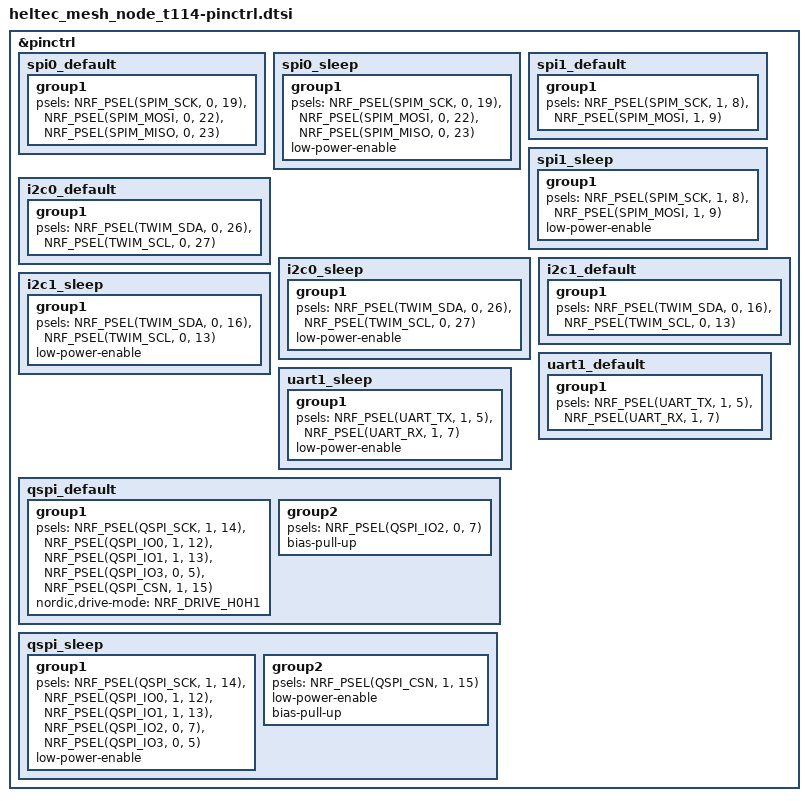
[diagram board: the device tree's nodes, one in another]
/*
 * Copyright (c) 2026 Yeray Lois Sanchez
 *
 * SPDX-License-Identifier: Apache-2.0
 */

&pinctrl {
	spi0_default: spi0_default {
		group1 {
			psels = <NRF_PSEL(SPIM_SCK, 0, 19)>,
				<NRF_PSEL(SPIM_MOSI, 0, 22)>,
				<NRF_PSEL(SPIM_MISO, 0, 23)>;
		};
	};

	spi0_sleep: spi0_sleep {
		group1 {
			psels = <NRF_PSEL(SPIM_SCK, 0, 19)>,
				<NRF_PSEL(SPIM_MOSI, 0, 22)>,
				<NRF_PSEL(SPIM_MISO, 0, 23)>;
			low-power-enable;
		};
	};

	spi1_default: spi1_default {
		group1 {
			psels = <NRF_PSEL(SPIM_SCK, 1, 8)>,
				<NRF_PSEL(SPIM_MOSI, 1, 9)>;
		};
	};

	spi1_sleep: spi1_sleep {
		group1 {
			psels = <NRF_PSEL(SPIM_SCK, 1, 8)>,
				<NRF_PSEL(SPIM_MOSI, 1, 9)>;
			low-power-enable;
		};
	};

	i2c0_default: i2c0_default {
		group1 {
			psels = <NRF_PSEL(TWIM_SDA, 0, 26)>,
				<NRF_PSEL(TWIM_SCL, 0, 27)>;
		};
	};

	i2c0_sleep: i2c0_sleep {
		group1 {
			psels = <NRF_PSEL(TWIM_SDA, 0, 26)>,
				<NRF_PSEL(TWIM_SCL, 0, 27)>;
			low-power-enable;
		};
	};

	i2c1_default: i2c1_default {
		group1 {
			psels = <NRF_PSEL(TWIM_SDA, 0, 16)>,
				<NRF_PSEL(TWIM_SCL, 0, 13)>;
		};
	};

	i2c1_sleep: i2c1_sleep {
		group1 {
			psels = <NRF_PSEL(TWIM_SDA, 0, 16)>,
				<NRF_PSEL(TWIM_SCL, 0, 13)>;
			low-power-enable;
		};
	};

	uart1_default: uart1_default {
		group1 {
			psels = <NRF_PSEL(UART_TX, 1, 5)>,
				<NRF_PSEL(UART_RX, 1, 7)>;
		};
	};

	uart1_sleep: uart1_sleep {
		group1 {
			psels = <NRF_PSEL(UART_TX, 1, 5)>,
				<NRF_PSEL(UART_RX, 1, 7)>;
			low-power-enable;
		};
	};

	qspi_default: qspi_default {
		group1 {
			psels = <NRF_PSEL(QSPI_SCK, 1, 14)>,
				<NRF_PSEL(QSPI_IO0, 1, 12)>,
				<NRF_PSEL(QSPI_IO1, 1, 13)>,
				<NRF_PSEL(QSPI_IO3, 0, 5)>,
				<NRF_PSEL(QSPI_CSN, 1, 15)>;
			nordic,drive-mode = <NRF_DRIVE_H0H1>;
		};

		group2 {
			psels = <NRF_PSEL(QSPI_IO2, 0, 7)>;
			bias-pull-up;
		};
	};

	qspi_sleep: qspi_sleep {
		group1 {
			psels = <NRF_PSEL(QSPI_SCK, 1, 14)>,
				<NRF_PSEL(QSPI_IO0, 1, 12)>,
				<NRF_PSEL(QSPI_IO1, 1, 13)>,
				<NRF_PSEL(QSPI_IO2, 0, 7)>,
				<NRF_PSEL(QSPI_IO3, 0, 5)>;
			low-power-enable;
		};

		group2 {
			psels = <NRF_PSEL(QSPI_CSN, 1, 15)>;
			low-power-enable;
			bias-pull-up;
		};
	};
};
